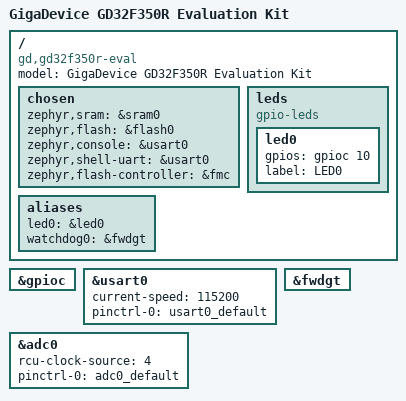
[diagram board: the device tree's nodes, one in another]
/*
 * Copyright (c) 2021 BrainCo Inc.
 * SPDX-License-Identifier: Apache-2.0
 */

/dts-v1/;

#include <gd/gd32f3x0/gd32f350rb.dtsi>
#include "gd32f350r_eval-pinctrl.dtsi"

/ {
	model = "GigaDevice GD32F350R Evaluation Kit";
	compatible = "gd,gd32f350r-eval";

	chosen {
		zephyr,sram = &sram0;
		zephyr,flash = &flash0;
		zephyr,console = &usart0;
		zephyr,shell-uart = &usart0;
		zephyr,flash-controller = &fmc;
	};

	leds {
		compatible = "gpio-leds";
		led0: led0 {
			gpios = <&gpioc 10 GPIO_ACTIVE_HIGH>;
			label = "LED0";
		};
	};

	aliases {
		led0 = &led0;
		watchdog0 = &fwdgt;
	};
};

&gpioc {
	status = "okay";
};

&usart0 {
	status = "okay";
	current-speed = <115200>;
	pinctrl-0 = <&usart0_default>;
	pinctrl-names = "default";
};

&adc0 {
	status = "okay";
	/* Set ADC0 clock source to RCU_ADCCK_APB2_DIV4. */
	rcu-clock-source = <4>;
	pinctrl-0 = <&adc0_default>;
	pinctrl-names = "default";
};

&fwdgt {
	status = "okay";
};
